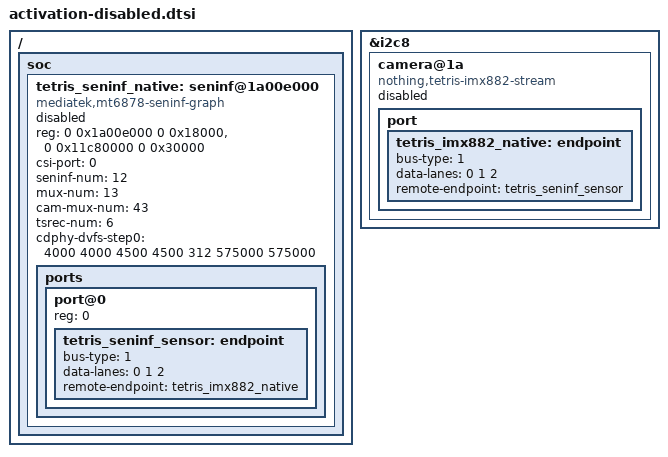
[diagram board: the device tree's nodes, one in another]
/* SPDX-License-Identifier: GPL-2.0-only */
/* Research include after 0055's disabled camera fixture. No live providers.
 * Addresses/counts/step0 from ee2 mt6878.dts SENINF core, not a phone dump.
 * Supplier phandles are deliberately NOT fabricated: native CSI mux clocks,
 * DVFSRC VCORE and rg_csi nvmem must be integrated before this is activatable.
 */
/ {
	soc {
		tetris_seninf_native: seninf@1a00e000 {
			compatible = "mediatek,mt6878-seninf-graph";
			reg = <0 0x1a00e000 0 0x18000>, <0 0x11c80000 0 0x30000>;
			reg-names = "base", "ana-rx";
			status = "disabled";
			csi-port = "0";
			seninf-num = <12>;
			mux-num = <13>;
			cam-mux-num = <43>;
			tsrec-num = <6>;
			cdphy-dvfs-step0 = <4000 4000 4500 4500 312 575000 575000>;
			/* Before activation: named IRQs; CAM_MAIN/CSI_RX genpd;
			 * 12 named clocks; VCORE regulator; rg_csi nvmem cell;
			 * receiver->CAMSV media endpoint and real DMA/IOMMU owner.
			 * Missing suppliers must fail probe, never use a fallback.
			 */
			ports {
				#address-cells = <1>;
				#size-cells = <0>;
				port@0 {
					reg = <0>;
					tetris_seninf_sensor: endpoint {
						bus-type = <1>; /* V4L2_FWNODE_BUS_TYPE_CSI2_CPHY */
						data-lanes = <0 1 2>;
						remote-endpoint = <&tetris_imx882_native>;
					};
				};
			};
		};
	};
};

&i2c8 {
	camera@1a {
		compatible = "nothing,tetris-imx882-stream";
		status = "disabled";
		port {
			tetris_imx882_native: endpoint {
				bus-type = <1>;
				data-lanes = <0 1 2>;
				remote-endpoint = <&tetris_seninf_sensor>;
			};
		};
	};
};
